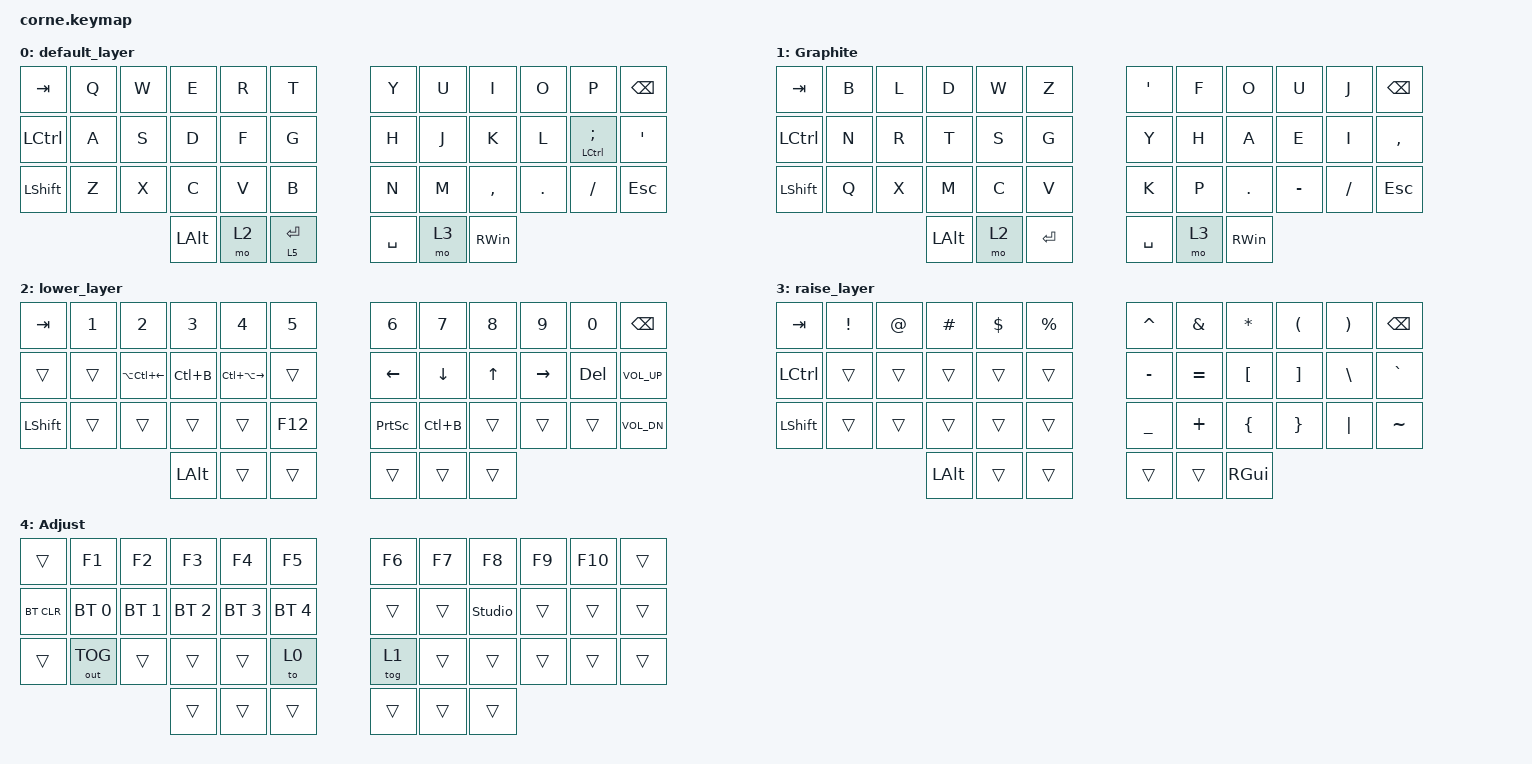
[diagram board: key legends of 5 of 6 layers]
#include <dt-bindings/zmk/mouse.h>
#include <behaviors/mouse_keys.dtsi>
#include <behaviors.dtsi>
#include <dt-bindings/zmk/bt.h>
#include <dt-bindings/zmk/keys.h>
#include <dt-bindings/zmk/outputs.h>

&lt {
    tapping-term-ms = <240>;
    flavor = "balanced";
    quick-tap-ms = <150>;
};

/ {
    behaviors {
        HMR: HMR {
            compatible = "zmk,behavior-hold-tap";
            label = "HMR";
            bindings = <&kp>, <&kp>;

            #binding-cells = <2>;
            tapping-term-ms = <280>;
            quick-tap-ms = <175>;
            flavor = "tap-preferred";
            hold-trigger-on-release;
            hold-trigger-key-positions = <0 13 1 12 24 25 26 14 2 3 15 27 28 17 5 4 16 29 36 37 38 0 1 2 3 4 5 12 13 14 15 16 17 24 25 26 27 28 29 36 37 38>;
        };

        HML: HML {
            compatible = "zmk,behavior-hold-tap";
            label = "HML";
            bindings = <&kp>, <&kp>;

            #binding-cells = <2>;
            tapping-term-ms = <280>;
            quick-tap-ms = <175>;
            flavor = "tap-preferred";
            hold-trigger-key-positions = <6 7 8 9 10 11 18 19 20 21 22 23 30 31 32 33 34 35 39 40 41>;
            hold-trigger-on-release;
        };
    };

    combos {
        compatible = "zmk,combos";

        Layer4 {
            bindings = <&mo 4>;
            key-positions = <37 40>;
        };
    };

    keymap {
        compatible = "zmk,keymap";

        default_layer {
            // -----------------------------------------------------------------------------------------
            // |  TAB |  Q  |  W  |  E  |  R  |  T  |   |  Y  |  U   |  I  |  O  |  P  | BKSP |
            // | CTRL |  A  |  S  |  D  |  F  |  G  |   |  H  |  J   |  K  |  L  |  ;  |  '   |
            // | SHFT |  Z  |  X  |  C  |  V  |  B  |   |  N  |  M   |  ,  |  .  |  /  | ESC  |
            //                    | ALT | LWR | SPC |   | ENT | RSE  | WIN |

            bindings = <
&kp TAB    &kp Q  &kp W  &kp E     &kp R  &kp T          &kp Y      &kp U  &kp I          &kp O    &kp P                   &kp BSPC
&kp LCTRL  &kp A  &kp S  &kp D     &kp F  &kp G          &kp H      &kp J  &kp K          &kp L    &HMR LEFT_CONTROL SEMI  &kp SQT
&kp LSHFT  &kp Z  &kp X  &kp C     &kp V  &kp B          &kp N      &kp M  &kp COMMA      &kp DOT  &kp FSLH                &kp ESC
                         &kp LALT  &mo 2  &lt 5 ENTER    &kp SPACE  &mo 3  &kp RIGHT_WIN
            >;
        };

        Graphite {
            // -----------------------------------------------------------------------------------------
            // |  TAB  |  B  |  L  |  D  |  W  |  Z  |   |  '  |  F  |  O  |  U  |  J  | BKSP |
            // | CTRL |  N  |  R  |  T  |  S  |  G  |   |  Y  |  H  |  A  |  E  |  I  |  ,   |
            // | SHFT |  Q  |  X  |  M  |  C  |  V  |   |  K  |  P  |  .  |  -  |  /  | ESC  |
            //                    | ALT | LWR | SPC |   | ENT | RSE  | WIN |

            bindings = <
&kp TAB    &kp B  &kp L  &kp D     &kp W  &kp Z      &kp SQT    &kp F  &kp O          &kp U      &kp J     &kp BSPC
&kp LCTRL  &kp N  &kp R  &kp T     &kp S  &kp G      &kp Y      &kp H  &kp A          &kp E      &kp I     &kp COMMA
&kp LSHFT  &kp Q  &kp X  &kp M     &kp C  &kp V      &kp K      &kp P  &kp DOT        &kp MINUS  &kp FSLH  &kp ESC
                         &kp LALT  &mo 2  &kp RET    &kp SPACE  &mo 3  &kp RIGHT_WIN
            >;
        };

        lower_layer {
            // -----------------------------------------------------------------------------------------
            // |  TAB |  1  |  2  |  3  |  4  |  5  |   |  6  |  7  |  8  |  9  |  0  | BKSP |
            // | BTCLR| BT1 | BT2 | BT3 | BT4 | BT5 |   | LFT | DWN |  UP | RGT |     |      |
            // | SHFT |     |     |     |     |     |   |     |     |     |     |     |      |
            //                    | GUI |     | SPC |   | ENT |     | ALT |

            bindings = <
&kp TAB    &kp N1  &kp N2            &kp N3     &kp N4             &kp N5     &kp N6     &kp N7     &kp N8  &kp N9     &kp N0   &kp BSPC
&trans     &trans  &kp LA(LC(LEFT))  &kp LC(B)  &kp LC(LA(RIGHT))  &trans     &kp LEFT   &kp DOWN   &kp UP  &kp RIGHT  &kp DEL  &kp C_VOL_UP
&kp LSHFT  &trans  &trans            &trans     &trans             &kp F12    &kp PSCRN  &kp LC(B)  &trans  &trans     &trans   &kp C_VOL_DN
                                     &kp LALT   &trans             &trans     &trans     &trans     &trans
            >;
        };

        raise_layer {
            // -----------------------------------------------------------------------------------------
            // |  TAB |  !  |  @  |  #  |  $  |  %  |   |  ^  |  &  |  *  |  (  |  )  | BKSP |
            // | CTRL |     |     |     |     |     |   |  -  |  =  |  [  |  ]  |  \  |  `   |
            // | SHFT |     |     |     |     |     |   |  _  |  +  |  {  |  }  | "|" |  ~   |
            //                    | GUI |     | SPC |   | ENT |     | ALT |

            bindings = <
&kp TAB    &kp EXCL  &kp AT  &kp HASH  &kp DLLR  &kp PRCNT    &kp CARET  &kp AMPS   &kp ASTRK  &kp LPAR  &kp RPAR  &kp BSPC
&kp LCTRL  &trans    &trans  &trans    &trans    &trans       &kp MINUS  &kp EQUAL  &kp LBKT   &kp RBKT  &kp BSLH  &kp GRAVE
&kp LSHFT  &trans    &trans  &trans    &trans    &trans       &kp UNDER  &kp PLUS   &kp LBRC   &kp RBRC  &kp PIPE  &kp TILDE
                             &kp LALT  &trans    &trans       &trans     &trans     &kp RGUI
            >;
        };

        Adjust {
            bindings = <
&trans      &kp F1        &kp F2        &kp F3        &kp F4        &kp F5          &kp F6  &kp F7  &kp F8  &kp F9  &kp F10  &trans
&bt BT_CLR  &bt BT_SEL 0  &bt BT_SEL 1  &bt BT_SEL 2  &bt BT_SEL 3  &bt BT_SEL 4    &trans  &trans  &studio_unlock  &trans  &trans   &trans
&trans      &out OUT_TOG  &trans        &trans        &trans        &to 0           &tog 1  &trans  &trans  &trans  &trans   &trans
                                        &trans        &trans        &trans          &trans  &trans  &trans
            >;
        };

        Mouse {
            bindings = <
&trans     &trans  &trans     &trans     &trans     &trans       &trans  &trans  &trans  &trans  &trans  &trans
&trans     &trans  &mkp RCLK  &mkp MCLK  &mkp LCLK  &trans       &trans  &trans  &trans  &trans  &trans  &trans
&mkp MCLK  &trans  &trans     &trans     &trans     &trans       &trans  &trans  &trans  &trans  &trans  &mkp LCLK
                              &mkp LCLK  &mkp LCLK  &mkp RCLK    &trans  &trans
            >;
        };
    };
};
